# R7FA6T1 register map
Vendor: Renesas; Series: RA6; File version: 1.2
CPU: CM4 r0p1, little endian, MPU, FPU, VTOR, 4 interrupt priority bits
Registers are 8-bit, read-write, reset 0x0 unless marked. A register's access mark holds for its fields unless they carry their own. Offsets are from the block's base; [hi:lo] are bit positions; {n}, {i} and the like mark numbered series.

## PMISC — Miscellaneous Port Control Register
Base 0x40040D00
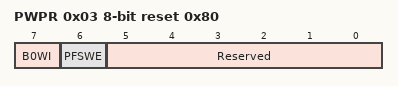
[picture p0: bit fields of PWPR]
0x03 PWPR reset 0x80 — Write-Protect Register
  [7] B0WI — PFSWE Bit Write Disable
    0=Writing to the PFSWE bit is enabled; 1=Writing to the PFSWE bit is disabled
  [6] PFSWE — PFS Register Write Enable
    0=Writing to the PFS register is disabled; 1=Writing to the PFS register is enabled
  [5:0] Reserved — These bits are read as 000000. The write value should be 000000.

## ELC — Event Link Controller
Base 0x40041000
0x00 ELCR — Event Link Controller Register
  [7] ELCON — All Event Link Enable
    0=Disable ELC function; 1=Enable ELC function
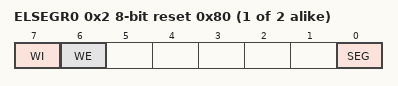
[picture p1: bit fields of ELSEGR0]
{0x2+2i} ELSEGR{i} (i=0..1) reset 0x80 — Event Link Software Event Generation Register {i}
  [7] WI wo — ELSEGR Register Write Disable
    0=Enable writes to ELSEGR register; 1=Disable writes to ELSEGR register
  [6] WE — SEG Bit Write Enable
    0=Disable writes to SEG bit; 1=Enable writes to SEG bit
  [0] SEG wo — Software Event Generation
    0=Normal operation; 1=Generate a software event
{0x10+4i} ELSR{i} (i=0..18) 16-bit — Event Link Setting Register {i}
  [8:0] ELS — Event Link Select
    0=Event output to the corresponding peripheral module is disabled; other=others (Set the number for the event signal to be linked.)

## POEG — Port Output Enable Module for GPT
Base 0x40042000
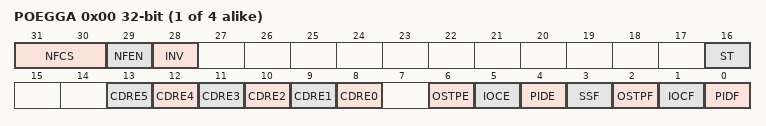
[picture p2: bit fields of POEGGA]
0x00 POEGG{x} (x=A,B,C,D; step 0x100) 32-bit — POEG Group {x} Setting Register
  [31:30] NFCS — Noise Filter Clock Select
    0=Sampling GTETRG pin input level for three times in every PCLKB; 1=Sampling GTETRG pin input level for three times in every PCLKB /8; 2=Sampling GTETRG pin input level for three times in every PCLKB /32; 3=Sampling GTETRG pin input level for three times in every PCLKB /128
  [29] NFEN — Noise Filter Enable
    0=Filtering noise disabled; 1=Filtering noise enabled
  [28] INV — GTETRG Input Reverse
    0=GTETRG Input; 1=GTETRG Input Reversed
  [16] ST ro — GTETRG Input Status Flag
    0=GTETRG input after filtering is 0; 1=GTETRG input after filtering is 1
  [n+8] CDRE{n} (n=0..5) — Comparator Disable Request Enable {n}Note: Can be modified only once after a reset.
    0=A disable request of comparator {n} disabled; 1=A disable request of comparator {n} enabled
  [6] OSTPE — Oscillation Stop Detection EnableNote: Can be modified only once after a reset.
    0=A output-disable request from the oscillation stop detection disabled; 1=A output-disable request from the oscillation stop detection enabled
  [5] IOCE — Enable for GPT Output-Disable RequestNote: Can be modified only once after a reset.
    0=Disable output-disable requests from GPT disable request; 1=Enable output-disable requests from GPT disable request
  [4] PIDE — Port Input Detection EnableNote: Can be modified only once after a reset.
    0=A output-disable request from the GTETRG pins disabled; 1=A output-disable request from the GTETRG pins enabled
  [3] SSF — Software Stop Flag
    0=A output-disable request from software has not been generated; 1=A output-disable request from software has been generated
  [2] OSTPF write-0-clears read-modifies — Oscillation Stop Detection Flag
    0=A output-disable request from the oscillation stop detection has not been generated; 1=A output-disable request from the oscillation stop detection has been generated
  [1] IOCF write-0-clears read-modifies — Real Time Overcurrent Detection Flag
    0=A output-disable request from GPT disable request or comparator interrupt has not been generated; 1=A output-disable request from GPT disable request or comparator interrupt has been generated
  [0] PIDF write-0-clears read-modifies — Port Input Detection Flag
    0=A output-disable request from the GTETRG pin has not been generated; 1=A output-disable request from the GTETRG pin has been generated
